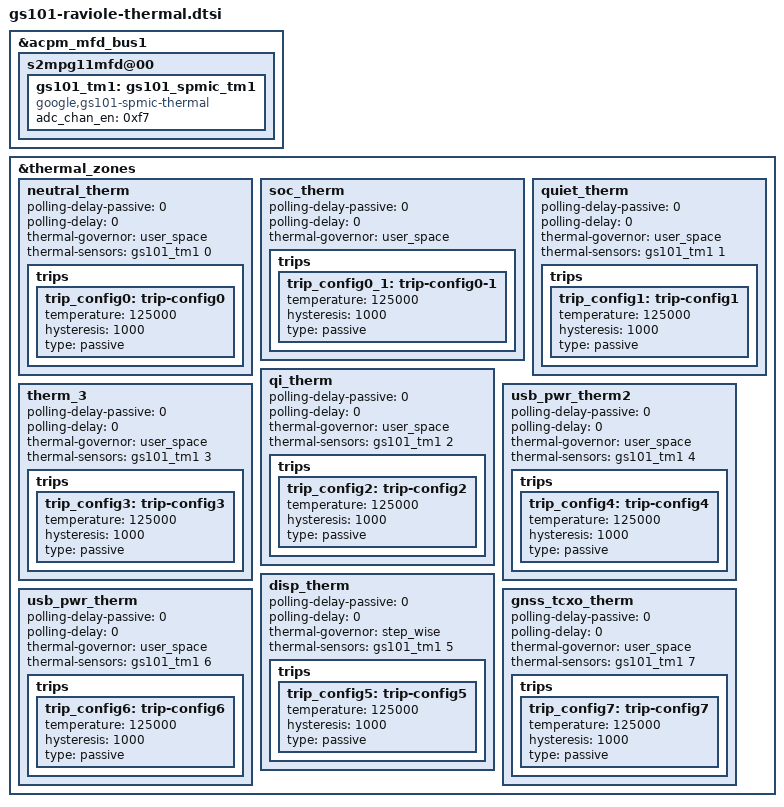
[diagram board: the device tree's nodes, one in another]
// SPDX-License-Identifier: GPL-2.0
/*
 * Google GS101 Raviole-specific thermal device tree source
 *
 * Copyright (c) 2020 Google, LLC
 *		https://www.google.com
 */

#include <dt-bindings/thermal/thermal.h>

&acpm_mfd_bus1 {
	s2mpg11mfd@00 {
		gs101_tm1: gs101_spmic_tm1 {
			compatible = "google,gs101-spmic-thermal";
			#thermal-sensor-cells = <1>;
			adc_chan_en = /bits/ 8 <0xf7>;
		};
	};
};

/* Thermal Zones */
&thermal_zones {
	neutral_therm {
		polling-delay-passive = <0>;
		polling-delay = <0>;
		thermal-governor = "user_space";
		thermal-sensors = <&gs101_tm1 0>;
		trips {
			trip_config0: trip-config0 {
				temperature = <125000>;
				hysteresis = <1000>;
				type = "passive";
			};
		};
	};
	/* TODO: remove this part after thermalHAL config removes soc_therm */
	soc_therm {
		polling-delay-passive = <0>;
		polling-delay = <0>;
		thermal-governor = "user_space";
		trips {
			trip_config0_1: trip-config0-1 {
				temperature = <125000>;
				hysteresis = <1000>;
				type = "passive";
			};
		};
	};
	quiet_therm {
		polling-delay-passive = <0>;
		polling-delay = <0>;
		thermal-governor = "user_space";
		thermal-sensors = <&gs101_tm1 1>;
		trips {
			trip_config1: trip-config1 {
				temperature = <125000>;
				hysteresis = <1000>;
				type = "passive";
			};
		};
	};
	qi_therm {
		polling-delay-passive = <0>;
		polling-delay = <0>;
		thermal-governor = "user_space";
		thermal-sensors = <&gs101_tm1 2>;
		trips {
			trip_config2: trip-config2 {
				temperature = <125000>;
				hysteresis = <1000>;
				type = "passive";
			};
		};
	};
	therm_3 {
		polling-delay-passive = <0>;
		polling-delay = <0>;
		thermal-governor = "user_space";
		thermal-sensors = <&gs101_tm1 3>;
		trips {
			trip_config3: trip-config3 {
				temperature = <125000>;
				hysteresis = <1000>;
				type = "passive";
			};
		};
	};
	usb_pwr_therm2 {
		polling-delay-passive = <0>;
		polling-delay = <0>;
		thermal-governor = "user_space";
		thermal-sensors = <&gs101_tm1 4>;
		trips {
			trip_config4: trip-config4 {
				temperature = <125000>;
				hysteresis = <1000>;
				type = "passive";
			};
		};
	};
	disp_therm {
		polling-delay-passive = <0>;
		polling-delay = <0>;
		thermal-governor = "step_wise";
		thermal-sensors = <&gs101_tm1 5>;
		trips {
			trip_config5: trip-config5 {
				temperature = <125000>;
				hysteresis = <1000>;
				type = "passive";
			};
		};
	};
	usb_pwr_therm: usb_pwr_therm {
		polling-delay-passive = <0>;
		polling-delay = <0>;
		thermal-governor = "user_space";
		thermal-sensors = <&gs101_tm1 6>;
		trips {
			trip_config6: trip-config6 {
				temperature = <125000>;
				hysteresis = <1000>;
				type = "passive";
			};
		};
	};
	gnss_tcxo_therm {
		polling-delay-passive = <0>;
		polling-delay = <0>;
		thermal-governor = "user_space";
		thermal-sensors = <&gs101_tm1 7>;
		trips {
			trip_config7: trip-config7 {
				temperature = <125000>;
				hysteresis = <1000>;
				type = "passive";
			};
		};
	};
};
